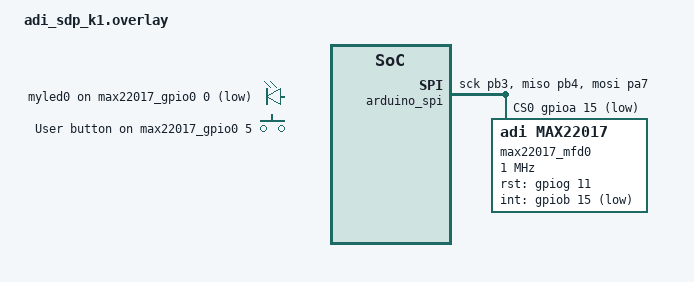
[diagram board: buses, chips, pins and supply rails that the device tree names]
/ {
	aliases {
		led0 = &myled0;
		sw0  = &button0;
	};

	leds {
		compatible = "gpio-leds";
		myled0: led_0 {
			gpios = <&max22017_gpio0 0 GPIO_ACTIVE_LOW>;
		};
	};

	buttons {
		compatible = "gpio-keys";
		button0: button_0 {
		gpios = <&max22017_gpio0 5 GPIO_ACTIVE_HIGH>;
		label = "User button";
		};
	};
};

&arduino_spi {
	status = "okay";
	pinctrl-names = "default";
	pinctrl-0 = <&spi1_sck_pb3 &spi1_miso_pb4 &spi1_mosi_pa7>;
	cs-gpios = <&gpioa 15 (GPIO_ACTIVE_LOW | GPIO_PULL_UP)>;

	max22017_mfd0: max22017_mfd@0 {
		compatible = "adi,max22017";
		spi-max-frequency = <1000000>;
		reg = <0>;
		rst-gpios = <&gpiog 11 GPIO_ACTIVE_HIGH>;
		int-gpios = <&gpiob 15 GPIO_ACTIVE_LOW>;
		crc-mode;
		status = "okay";

		max22017_gpio0: max22017-gpio {
			compatible = "adi,max22017-gpio";
			gpio-controller;
			ngpios = <5>;
			#gpio-cells = <2>;
			status = "okay";
		};
	};
};
